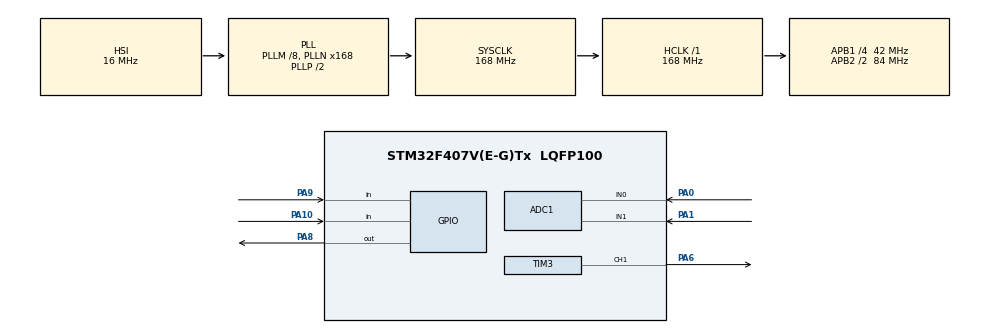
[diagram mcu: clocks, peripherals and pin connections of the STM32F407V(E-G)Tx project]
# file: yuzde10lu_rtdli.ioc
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ADC1.Channel-2\#ChannelRegularConversion=ADC_CHANNEL_1
ADC1.Channel-3\#ChannelRegularConversion=ADC_CHANNEL_0
ADC1.ContinuousConvMode=ENABLE
ADC1.DMAContinuousRequests=ENABLE
ADC1.EOCSelection=ADC_EOC_SEQ_CONV
ADC1.ExternalTrigConv=ADC_SOFTWARE_START
ADC1.NbrOfConversion=2
ADC1.NbrOfConversionFlag=1
ADC1.Rank-2\#ChannelRegularConversion=1
ADC1.Rank-3\#ChannelRegularConversion=2
ADC1.SamplingTime-2\#ChannelRegularConversion=ADC_SAMPLETIME_56CYCLES
ADC1.SamplingTime-3\#ChannelRegularConversion=ADC_SAMPLETIME_56CYCLES
ADC1.master=1
Dma.ADC1.0.Direction=DMA_PERIPH_TO_MEMORY
Dma.ADC1.0.FIFOMode=DMA_FIFOMODE_DISABLE
Dma.ADC1.0.Instance=DMA2_Stream4
Dma.ADC1.0.MemDataAlignment=DMA_MDATAALIGN_WORD
Dma.ADC1.0.MemInc=DMA_MINC_ENABLE
Dma.ADC1.0.Mode=DMA_CIRCULAR
Dma.ADC1.0.PeriphDataAlignment=DMA_PDATAALIGN_WORD
Dma.ADC1.0.PeriphInc=DMA_PINC_DISABLE
Dma.ADC1.0.Priority=DMA_PRIORITY_VERY_HIGH
Dma.Request0=ADC1
Mcu.Family=STM32F4
Mcu.Name=STM32F407V(E-G)Tx
Mcu.Package=LQFP100
NVIC.DMA2_Stream4_IRQn=true\:0\:0\:false\:false\:true\:false\:true\:true
NVIC.PriorityGroup=NVIC_PRIORITYGROUP_4
PA0-WKUP.Signal=ADCx_IN0
PA1.Signal=ADCx_IN1
PA10.GPIO_PuPd=GPIO_PULLUP
PA10.Signal=GPIO_Input
PA6.Signal=S_TIM3_CH1
PA8.Signal=GPIO_Output
PA9.GPIO_PuPd=GPIO_PULLUP
PA9.Signal=GPIO_Input
PH0-OSC_IN.Mode=HSE-External-Oscillator
PH0-OSC_IN.Signal=RCC_OSC_IN
PH1-OSC_OUT.Mode=HSE-External-Oscillator
PH1-OSC_OUT.Signal=RCC_OSC_OUT
ProjectManager.HeapSize=0x200
ProjectManager.StackSize=0x400
ProjectManager.TargetToolchain=STM32CubeIDE
RCC.48MHZClocksFreq_Value=84000000
RCC.AHBFreq_Value=168000000
RCC.APB1CLKDivider=RCC_HCLK_DIV4
RCC.APB1Freq_Value=42000000
RCC.APB1TimFreq_Value=84000000
RCC.APB2CLKDivider=RCC_HCLK_DIV2
RCC.APB2Freq_Value=84000000
RCC.APB2TimFreq_Value=168000000
RCC.CortexFreq_Value=168000000
RCC.HCLKFreq_Value=168000000
RCC.HSE_VALUE=25000000
RCC.HSI_VALUE=16000000
RCC.LSE_VALUE=32768
RCC.PLLM=8
RCC.PLLN=168
RCC.SYSCLKFreq_VALUE=168000000
RCC.SYSCLKSource=RCC_SYSCLKSOURCE_PLLCLK
RCC.VCOOutputFreq_Value=336000000
SH.ADCx_IN0.0=ADC1_IN0,IN0
SH.ADCx_IN1.0=ADC1_IN1,IN1
SH.S_TIM3_CH1.0=TIM3_CH1,PWM Generation1 CH1
TIM14.Period=3000
TIM14.Prescaler=16799
TIM3.Channel-PWM\ Generation1\ CH1=TIM_CHANNEL_1
TIM3.Period=49
TIM3.Prescaler=83
TIM4.Period=0xffff
TIM4.Prescaler=8399
VP_TIM14_VS_ClockSourceINT.Mode=Enable_Timer
VP_TIM3_VS_ClockSourceINT.Mode=Internal
VP_TIM4_VS_ClockSourceINT.Mode=Internal
board=custom

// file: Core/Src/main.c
/* USER CODE BEGIN Header */
/**
  ******************************************************************************
  * @file           : main.c
  * @brief          : Main program body
  ******************************************************************************
  * @attention
  *
  * Copyright (c) 2025 STMicroelectronics.
  * All rights reserved.
  *
  * This software is licensed under terms that can be found in the LICENSE file
  * in the root directory of this software component.
  * If no LICENSE file comes with this software, it is provided AS-IS.
  *
  ******************************************************************************
  */
/* USER CODE END Header */
#include "main.h"

/* USER CODE BEGIN Includes */
#include "apps.h"
#include "ready2drive.h"
#include <string.h>
#include <stdio.h>

/* USER CODE END Includes */

ADC_HandleTypeDef hadc1;
DMA_HandleTypeDef hdma_adc1;

TIM_HandleTypeDef htim3;
TIM_HandleTypeDef htim4;
TIM_HandleTypeDef htim14;

void SystemClock_Config(void);
static void MX_DMA_Init(void);
static void MX_GPIO_Init(void);
static void MX_ADC1_Init(void);
static void MX_TIM3_Init(void);
static void MX_TIM4_Init(void);
static void MX_TIM14_Init(void);

int main(void)
{

  /* MCU Configuration--------------------------------------------------------*/

  /* Reset of all peripherals, Initializes the Flash interface and the Systick. */
  HAL_Init();

  /* Configure the system clock */
  SystemClock_Config();

  /* Initialize all configured peripherals */
  MX_DMA_Init();
  MX_GPIO_Init();
  MX_ADC1_Init();
  MX_TIM3_Init();
  MX_TIM4_Init();
  MX_TIM14_Init();
  /* USER CODE BEGIN 2 */
  APPS_Deinit();
  R2D_Init();

  /* USER CODE END 2 */

  /* Infinite loop */
  /* USER CODE BEGIN WHILE */
  while (1)
  {
	  R2D_Loop();
  }
}
/* USER CODE BEGIN END */

void SystemClock_Config(void)
{
  RCC_OscInitTypeDef RCC_OscInitStruct = {0};
  RCC_ClkInitTypeDef RCC_ClkInitStruct = {0};

  /** Configure the main internal regulator output voltage
  */
  __HAL_RCC_PWR_CLK_ENABLE();
  __HAL_PWR_VOLTAGESCALING_CONFIG(PWR_REGULATOR_VOLTAGE_SCALE1);

  /** Initializes the RCC Oscillators according to the specified parameters
  * in the RCC_OscInitTypeDef structure.
  */
  RCC_OscInitStruct.OscillatorType = RCC_OSCILLATORTYPE_HSI;
  RCC_OscInitStruct.HSIState = RCC_HSI_ON;
  RCC_OscInitStruct.HSICalibrationValue = RCC_HSICALIBRATION_DEFAULT;
  RCC_OscInitStruct.PLL.PLLState = RCC_PLL_ON;
  RCC_OscInitStruct.PLL.PLLSource = RCC_PLLSOURCE_HSI;
  RCC_OscInitStruct.PLL.PLLM = 8;
  RCC_OscInitStruct.PLL.PLLN = 168;
  RCC_OscInitStruct.PLL.PLLP = RCC_PLLP_DIV2;
  RCC_OscInitStruct.PLL.PLLQ = 4;
  if (HAL_RCC_OscConfig(&RCC_OscInitStruct) != HAL_OK)
  {
    Error_Handler();
  }

  /** Initializes the CPU, AHB and APB buses clocks
  */
  RCC_ClkInitStruct.ClockType = RCC_CLOCKTYPE_HCLK|RCC_CLOCKTYPE_SYSCLK
                              |RCC_CLOCKTYPE_PCLK1|RCC_CLOCKTYPE_PCLK2;
  RCC_ClkInitStruct.SYSCLKSource = RCC_SYSCLKSOURCE_PLLCLK;
  RCC_ClkInitStruct.AHBCLKDivider = RCC_SYSCLK_DIV1;
  RCC_ClkInitStruct.APB1CLKDivider = RCC_HCLK_DIV4;
  RCC_ClkInitStruct.APB2CLKDivider = RCC_HCLK_DIV2;

  if (HAL_RCC_ClockConfig(&RCC_ClkInitStruct, FLASH_LATENCY_5) != HAL_OK)
  {
    Error_Handler();
  }
}

static void MX_ADC1_Init(void)
{

  ADC_ChannelConfTypeDef sConfig = {0};

  /** Configure the global features of the ADC (Clock, Resolution, Data Alignment and number of conversion)
  */
  hadc1.Instance = ADC1;
  hadc1.Init.ClockPrescaler = ADC_CLOCK_SYNC_PCLK_DIV4;
  hadc1.Init.Resolution = ADC_RESOLUTION_12B;
  hadc1.Init.ScanConvMode = ENABLE;
  hadc1.Init.ContinuousConvMode = ENABLE;
  hadc1.Init.DiscontinuousConvMode = DISABLE;
  hadc1.Init.ExternalTrigConvEdge = ADC_EXTERNALTRIGCONVEDGE_NONE;
  hadc1.Init.ExternalTrigConv = ADC_SOFTWARE_START;
  hadc1.Init.DataAlign = ADC_DATAALIGN_RIGHT;
  hadc1.Init.NbrOfConversion = 2;
  hadc1.Init.DMAContinuousRequests = ENABLE;
  hadc1.Init.EOCSelection = ADC_EOC_SEQ_CONV;
  if (HAL_ADC_Init(&hadc1) != HAL_OK)
  {
    Error_Handler();
  }

  /** Configure for the selected ADC regular channel its corresponding rank in the sequencer and its sample time.
  */
  sConfig.Channel = ADC_CHANNEL_1;
  sConfig.Rank = 1;
  sConfig.SamplingTime = ADC_SAMPLETIME_56CYCLES;
  if (HAL_ADC_ConfigChannel(&hadc1, &sConfig) != HAL_OK)
  {
    Error_Handler();
  }

  /** Configure for the selected ADC regular channel its corresponding rank in the sequencer and its sample time.
  */
  sConfig.Channel = ADC_CHANNEL_0;
  sConfig.Rank = 2;
  if (HAL_ADC_ConfigChannel(&hadc1, &sConfig) != HAL_OK)
  {
    Error_Handler();
  }

}

static void MX_TIM3_Init(void)
{

  TIM_ClockConfigTypeDef sClockSourceConfig = {0};
  TIM_MasterConfigTypeDef sMasterConfig = {0};
  TIM_OC_InitTypeDef sConfigOC = {0};

  htim3.Instance = TIM3;
  htim3.Init.Prescaler = 83;
  htim3.Init.CounterMode = TIM_COUNTERMODE_UP;
  htim3.Init.Period = 49;
  htim3.Init.ClockDivision = TIM_CLOCKDIVISION_DIV1;
  htim3.Init.AutoReloadPreload = TIM_AUTORELOAD_PRELOAD_DISABLE;
  if (HAL_TIM_Base_Init(&htim3) != HAL_OK)
  {
    Error_Handler();
  }
  sClockSourceConfig.ClockSource = TIM_CLOCKSOURCE_INTERNAL;
  if (HAL_TIM_ConfigClockSource(&htim3, &sClockSourceConfig) != HAL_OK)
  {
    Error_Handler();
  }
  if (HAL_TIM_PWM_Init(&htim3) != HAL_OK)
  {
    Error_Handler();
  }
  sMasterConfig.MasterOutputTrigger = TIM_TRGO_RESET;
  sMasterConfig.MasterSlaveMode = TIM_MASTERSLAVEMODE_DISABLE;
  if (HAL_TIMEx_MasterConfigSynchronization(&htim3, &sMasterConfig) != HAL_OK)
  {
    Error_Handler();
  }
  sConfigOC.OCMode = TIM_OCMODE_PWM1;
  sConfigOC.Pulse = 0;
  sConfigOC.OCPolarity = TIM_OCPOLARITY_HIGH;
  sConfigOC.OCFastMode = TIM_OCFAST_DISABLE;
  if (HAL_TIM_PWM_ConfigChannel(&htim3, &sConfigOC, TIM_CHANNEL_1) != HAL_OK)
  {
    Error_Handler();
  }
  HAL_TIM_MspPostInit(&htim3);

}

static void MX_TIM4_Init(void)
{

  TIM_ClockConfigTypeDef sClockSourceConfig = {0};
  TIM_MasterConfigTypeDef sMasterConfig = {0};

  htim4.Instance = TIM4;
  htim4.Init.Prescaler = 8399;
  htim4.Init.CounterMode = TIM_COUNTERMODE_UP;
  htim4.Init.Period = 0xffff;
  htim4.Init.ClockDivision = TIM_CLOCKDIVISION_DIV1;
  htim4.Init.AutoReloadPreload = TIM_AUTORELOAD_PRELOAD_DISABLE;
  if (HAL_TIM_Base_Init(&htim4) != HAL_OK)
  {
    Error_Handler();
  }
  sClockSourceConfig.ClockSource = TIM_CLOCKSOURCE_INTERNAL;
  if (HAL_TIM_ConfigClockSource(&htim4, &sClockSourceConfig) != HAL_OK)
  {
    Error_Handler();
  }
  sMasterConfig.MasterOutputTrigger = TIM_TRGO_RESET;
  sMasterConfig.MasterSlaveMode = TIM_MASTERSLAVEMODE_DISABLE;
  if (HAL_TIMEx_MasterConfigSynchronization(&htim4, &sMasterConfig) != HAL_OK)
  {
    Error_Handler();
  }

}

static void MX_TIM14_Init(void)
{

  htim14.Instance = TIM14;
  htim14.Init.Prescaler = 16799;
  htim14.Init.CounterMode = TIM_COUNTERMODE_UP;
  htim14.Init.Period = 3000;
  htim14.Init.ClockDivision = TIM_CLOCKDIVISION_DIV1;
  htim14.Init.AutoReloadPreload = TIM_AUTORELOAD_PRELOAD_DISABLE;
  if (HAL_TIM_Base_Init(&htim14) != HAL_OK)
  {
    Error_Handler();
  }

}

static void MX_DMA_Init(void)
{

  /* DMA controller clock enable */
  __HAL_RCC_DMA2_CLK_ENABLE();

  /* DMA interrupt init */
  /* DMA2_Stream4_IRQn interrupt configuration */
  HAL_NVIC_SetPriority(DMA2_Stream4_IRQn, 0, 0);
  HAL_NVIC_EnableIRQ(DMA2_Stream4_IRQn);

}

static void MX_GPIO_Init(void)
{
  GPIO_InitTypeDef GPIO_InitStruct = {0};

  /* GPIO Ports Clock Enable */
  __HAL_RCC_GPIOH_CLK_ENABLE();
  __HAL_RCC_GPIOA_CLK_ENABLE();

  /*Configure GPIO pin Output Level */
  HAL_GPIO_WritePin(GPIOA, GPIO_PIN_8, GPIO_PIN_RESET);

  /*Configure GPIO pin : PA8 */
  GPIO_InitStruct.Pin = GPIO_PIN_8;
  GPIO_InitStruct.Mode = GPIO_MODE_OUTPUT_PP;
  GPIO_InitStruct.Pull = GPIO_NOPULL;
  GPIO_InitStruct.Speed = GPIO_SPEED_FREQ_LOW;
  HAL_GPIO_Init(GPIOA, &GPIO_InitStruct);

  /*Configure GPIO pins : PA9 PA10 */
  GPIO_InitStruct.Pin = GPIO_PIN_9|GPIO_PIN_10;
  GPIO_InitStruct.Mode = GPIO_MODE_INPUT;
  GPIO_InitStruct.Pull = GPIO_PULLUP;
  HAL_GPIO_Init(GPIOA, &GPIO_InitStruct);

}

void Error_Handler(void)
{
  __disable_irq();
  while (1)
  {
  }
}
